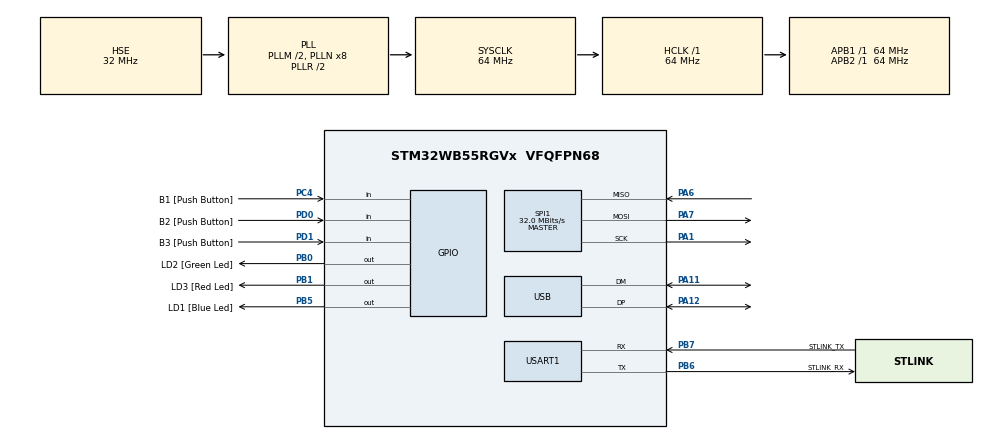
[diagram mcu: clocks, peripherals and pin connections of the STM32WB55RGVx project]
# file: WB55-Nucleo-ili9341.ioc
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Mcu.Family=STM32WB
Mcu.Name=STM32WB55RGVx
Mcu.Package=VFQFPN68
NVIC.PriorityGroup=NVIC_PRIORITYGROUP_4
OSC_IN.Mode=HSE-External-Oscillator
OSC_IN.Signal=RCC_OSC_IN
OSC_OUT.Mode=HSE-External-Oscillator
OSC_OUT.Signal=RCC_OSC_OUT
PA1.Mode=Full_Duplex_Master
PA1.Signal=SPI1_SCK
PA11.Mode=Device
PA11.Signal=USB_DM
PA12.Mode=Device
PA12.Signal=USB_DP
PA13.GPIO_Label=JTMS
PA13.Mode=Trace_Asynchronous_SW
PA13.Signal=SYS_JTMS-SWDIO
PA14.GPIO_Label=JTCK
PA14.Mode=Trace_Asynchronous_SW
PA14.Signal=SYS_JTCK-SWCLK
PA6.Mode=Full_Duplex_Master
PA6.Signal=SPI1_MISO
PA7.Mode=Full_Duplex_Master
PA7.Signal=SPI1_MOSI
PB0.GPIO_Label=LD2 [Green Led]
PB0.Signal=GPIO_Output
PB1.GPIO_Label=LD3 [Red Led]
PB1.Signal=GPIO_Output
PB3.GPIO_Label=JTDO
PB3.Mode=Trace_Asynchronous_SW
PB3.Signal=SYS_JTDO-SWO
PB5.GPIO_Label=LD1 [Blue Led]
PB5.Signal=GPIO_Output
PB6.GPIO_Label=STLINK_RX
PB6.GPIO_PuPd=GPIO_PULLUP
PB6.Mode=Asynchronous
PB6.Signal=USART1_TX
PB7.GPIO_Label=STLINK_TX
PB7.GPIO_PuPd=GPIO_PULLUP
PB7.Mode=Asynchronous
PB7.Signal=USART1_RX
PC13.Mode=SYS_WakeUp1
PC13.Signal=SYS_WKUP2
PC14-OSC32_IN.Mode=LSE-External-Oscillator
PC14-OSC32_IN.Signal=RCC_OSC32_IN
PC15-OSC32_OUT.Mode=LSE-External-Oscillator
PC15-OSC32_OUT.Signal=RCC_OSC32_OUT
PC4.GPIO_Label=B1 [Push Button]
PC4.Signal=GPIO_Input
PD0.GPIO_Label=B2 [Push Button]
PD0.Signal=GPIO_Input
PD1.GPIO_Label=B3 [Push Button]
PD1.Signal=GPIO_Input
ProjectManager.HeapSize=0x200
ProjectManager.StackSize=0x400
ProjectManager.TargetToolchain=STM32CubeIDE
RCC.ADCFreq_Value=48000000
RCC.AHB2CLKDivider=RCC_SYSCLK_DIV2
RCC.AHBFreq_Value=64000000
RCC.APB1Freq_Value=64000000
RCC.APB1TimFreq_Value=64000000
RCC.APB2Freq_Value=64000000
RCC.APB2TimFreq_Value=64000000
RCC.APB3Freq_Value=16000000
RCC.Cortex2_Div=SYSTICK_CLKSOURCE_HCLK_DIV8
RCC.CortexFreq_Value=64000000
RCC.HCLKFreq_Value=64000000
RCC.HSE_VALUE=32000000
RCC.HSI48_VALUE=48000000
RCC.HSI_VALUE=16000000
RCC.PLLM=RCC_PLLM_DIV2
RCC.PLLSAI1N=6
RCC.PLLSourceVirtual=RCC_PLLSOURCE_HSE
RCC.SMPSCLockSelectionVirtual=RCC_SMPSCLKSOURCE_HSI
RCC.SMPSCLockSelectionVirtualVirtual=RCC_SMPSCLKSOURCE_HSI
RCC.SMPSDivider=1
RCC.SYSCLKFreq_VALUE=64000000
RCC.SYSCLKSource=RCC_SYSCLKSOURCE_PLLCLK
RCC.USBFreq_Value=48000000
RCC.VCOOutputFreq_Value=128000000
SPI1.BaudRatePrescaler=SPI_BAUDRATEPRESCALER_2
SPI1.CalculateBaudRate=32.0 MBits/s
SPI1.Direction=SPI_DIRECTION_2LINES
SPI1.Mode=SPI_MODE_MASTER
SPI1.VirtualType=VM_MASTER
USART1.VirtualMode-Asynchronous=VM_ASYNC
USART1.WordLength=WORDLENGTH_7B
board=P-NUCLEO-WB55-Nucleo

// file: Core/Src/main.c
/* USER CODE BEGIN Header */
/**
  ******************************************************************************
  * @file           : main.c
  * @brief          : Main program body
  ******************************************************************************
  * @attention
  *
  * <h2><center>&copy; Copyright (c) 2020 STMicroelectronics.
  * All rights reserved.</center></h2>
  *
  * This software component is licensed by ST under BSD 3-Clause license,
  * the "License"; You may not use this file except in compliance with the
  * License. You may obtain a copy of the License at:
  *                        opensource.org/licenses/BSD-3-Clause
  *
  ******************************************************************************
  */
/* USER CODE END Header */
#include "main.h"
#include "spi.h"
#include "usart.h"
#include "usb.h"
#include "gpio.h"

/* USER CODE BEGIN Includes */
#include "stm32wbxx_nucleo_bsp.h"
#include "lcd.h"
/* USER CODE END Includes */

void SystemClock_Config(void);

/* USER CODE BEGIN 0 */
extern LCD_DrvTypeDef *G_lcd_drv_ptr; //TODO - perhaps this should start here or in main
extern LCD_DrvTypeDef G_ili9341_drv;

LCD_IO_CtrlTypeDef G_LcdIoCtrl;
/* USER CODE END 0 */

int main(void)
{

  /* MCU Configuration--------------------------------------------------------*/

  /* Reset of all peripherals, Initializes the Flash interface and the Systick. */
  HAL_Init();

  /* Configure the system clock */
  SystemClock_Config();

  /* Initialize all configured peripherals */
  MX_GPIO_Init();
  MX_USART1_UART_Init();
  MX_USB_PCD_Init();
  MX_SPI1_Init();
  /* USER CODE BEGIN 2 */

  //init G_LCD_IO
  //we are using function pointers so lower level functions don't need to be hard coded
  //and the driver is portable by just updating board specific functions
  G_LcdIoCtrl.WriteCommand      = &LCD_IO_WriteCommand;
  G_LcdIoCtrl.WriteData         = &LCD_IO_WriteData;
  G_LcdIoCtrl.WriteMultipleData = &LCD_IO_WriteMultipleData;
  G_LcdIoCtrl.Reset             = &LCD_IO_Reset;
  G_LcdIoCtrl.Delay             = &LCD_IO_Delay;

  LCD_IO_Init();

  LCD_Init(&G_ili9341_drv, &G_LcdIoCtrl);

  LCD_TestDemo(G_lcd_drv_ptr); // doesn't return
  /* USER CODE END 2 */

  /* Infinite loop */
  while (1)
  {

  }
}

void SystemClock_Config(void)
{
  RCC_OscInitTypeDef RCC_OscInitStruct = {0};
  RCC_ClkInitTypeDef RCC_ClkInitStruct = {0};
  RCC_PeriphCLKInitTypeDef PeriphClkInitStruct = {0};

  /** Configure the main internal regulator output voltage
  */
  __HAL_PWR_VOLTAGESCALING_CONFIG(PWR_REGULATOR_VOLTAGE_SCALE1);
  /** Initializes the RCC Oscillators according to the specified parameters
  * in the RCC_OscInitTypeDef structure.
  */
  RCC_OscInitStruct.OscillatorType = RCC_OSCILLATORTYPE_HSI|RCC_OSCILLATORTYPE_HSE;
  RCC_OscInitStruct.HSEState = RCC_HSE_ON;
  RCC_OscInitStruct.HSIState = RCC_HSI_ON;
  RCC_OscInitStruct.HSICalibrationValue = RCC_HSICALIBRATION_DEFAULT;
  RCC_OscInitStruct.PLL.PLLState = RCC_PLL_ON;
  RCC_OscInitStruct.PLL.PLLSource = RCC_PLLSOURCE_HSE;
  RCC_OscInitStruct.PLL.PLLM = RCC_PLLM_DIV2;
  RCC_OscInitStruct.PLL.PLLN = 8;
  RCC_OscInitStruct.PLL.PLLP = RCC_PLLP_DIV2;
  RCC_OscInitStruct.PLL.PLLR = RCC_PLLR_DIV2;
  RCC_OscInitStruct.PLL.PLLQ = RCC_PLLQ_DIV2;
  if (HAL_RCC_OscConfig(&RCC_OscInitStruct) != HAL_OK)
  {
    Error_Handler();
  }
  /** Configure the SYSCLKSource, HCLK, PCLK1 and PCLK2 clocks dividers
  */
  RCC_ClkInitStruct.ClockType = RCC_CLOCKTYPE_HCLK4|RCC_CLOCKTYPE_HCLK2
                              |RCC_CLOCKTYPE_HCLK|RCC_CLOCKTYPE_SYSCLK
                              |RCC_CLOCKTYPE_PCLK1|RCC_CLOCKTYPE_PCLK2;
  RCC_ClkInitStruct.SYSCLKSource = RCC_SYSCLKSOURCE_PLLCLK;
  RCC_ClkInitStruct.AHBCLKDivider = RCC_SYSCLK_DIV1;
  RCC_ClkInitStruct.APB1CLKDivider = RCC_HCLK_DIV1;
  RCC_ClkInitStruct.APB2CLKDivider = RCC_HCLK_DIV1;
  RCC_ClkInitStruct.AHBCLK2Divider = RCC_SYSCLK_DIV2;
  RCC_ClkInitStruct.AHBCLK4Divider = RCC_SYSCLK_DIV1;

  if (HAL_RCC_ClockConfig(&RCC_ClkInitStruct, FLASH_LATENCY_3) != HAL_OK)
  {
    Error_Handler();
  }
  /** Initializes the peripherals clocks
  */
  PeriphClkInitStruct.PeriphClockSelection = RCC_PERIPHCLK_SMPS|RCC_PERIPHCLK_USART1
                              |RCC_PERIPHCLK_USB;
  PeriphClkInitStruct.PLLSAI1.PLLN = 6;
  PeriphClkInitStruct.PLLSAI1.PLLP = RCC_PLLP_DIV2;
  PeriphClkInitStruct.PLLSAI1.PLLQ = RCC_PLLQ_DIV2;
  PeriphClkInitStruct.PLLSAI1.PLLR = RCC_PLLR_DIV2;
  PeriphClkInitStruct.PLLSAI1.PLLSAI1ClockOut = RCC_PLLSAI1_USBCLK;
  PeriphClkInitStruct.Usart1ClockSelection = RCC_USART1CLKSOURCE_PCLK2;
  PeriphClkInitStruct.UsbClockSelection = RCC_USBCLKSOURCE_PLLSAI1;
  PeriphClkInitStruct.SmpsClockSelection = RCC_SMPSCLKSOURCE_HSI;
  PeriphClkInitStruct.SmpsDivSelection = RCC_SMPSCLKDIV_RANGE0;
  if (HAL_RCCEx_PeriphCLKConfig(&PeriphClkInitStruct) != HAL_OK)
  {
    Error_Handler();
  }
}

void Error_Handler(void)
{
}

/************************ (C) COPYRIGHT STMicroelectronics *****END OF FILE****/
